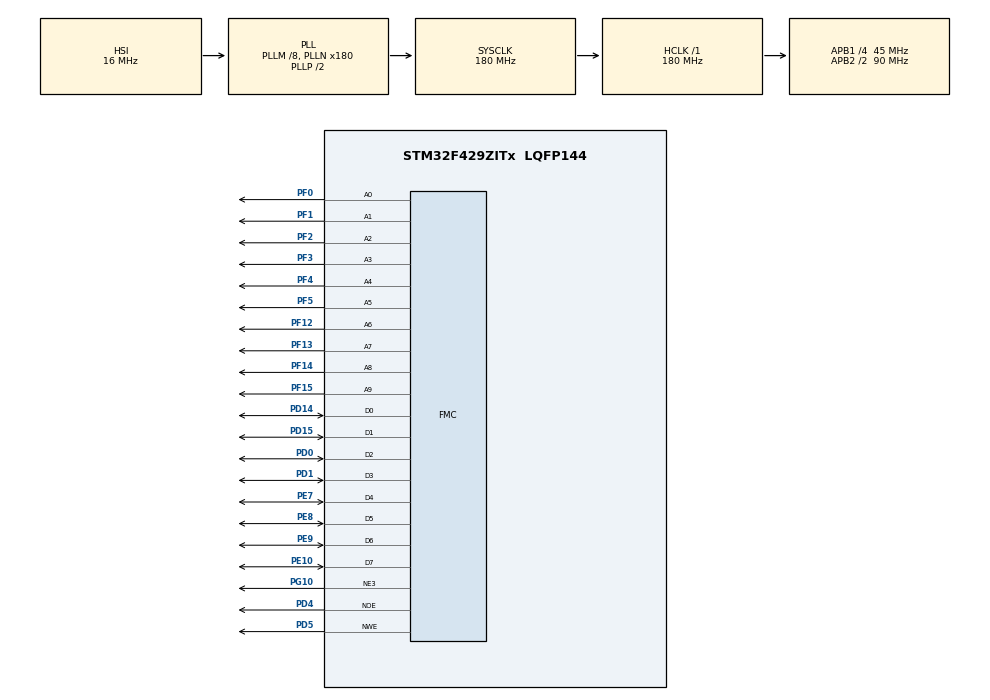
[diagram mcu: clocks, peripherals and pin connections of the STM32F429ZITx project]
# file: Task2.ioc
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FMC.ExtendedMode1=FMC_EXTENDED_MODE_ENABLE
FMC.WriteOperation1=FMC_WRITE_OPERATION_ENABLE
Mcu.Family=STM32F4
Mcu.Name=STM32F429ZITx
Mcu.Package=LQFP144
NVIC.PriorityGroup=NVIC_PRIORITYGROUP_4
PD0.Signal=FMC_D2_DA2
PD1.Signal=FMC_D3_DA3
PD14.Signal=FMC_D0_DA0
PD15.Signal=FMC_D1_DA1
PD4.Signal=FMC_NOE
PD5.Signal=FMC_NWE
PE10.Signal=FMC_D7_DA7
PE7.Signal=FMC_D4_DA4
PE8.Signal=FMC_D5_DA5
PE9.Signal=FMC_D6_DA6
PF0.Signal=FMC_A0
PF1.Signal=FMC_A1
PF12.Signal=FMC_A6
PF13.Signal=FMC_A7
PF14.Signal=FMC_A8
PF15.Signal=FMC_A9
PF2.Signal=FMC_A2
PF3.Signal=FMC_A3
PF4.Signal=FMC_A4
PF5.Signal=FMC_A5
PG10.Mode=NorPsramChipSelect3_1
PG10.Signal=FMC_NE3
PH0/OSC_IN.Mode=HSE-External-Oscillator
PH0/OSC_IN.Signal=RCC_OSC_IN
PH1/OSC_OUT.Mode=HSE-External-Oscillator
PH1/OSC_OUT.Signal=RCC_OSC_OUT
ProjectManager.HeapSize=0x200
ProjectManager.StackSize=0x400
ProjectManager.TargetToolchain=EWARM V8.32
RCC.48MHZClocksFreq_Value=90000000
RCC.AHBFreq_Value=180000000
RCC.APB1CLKDivider=RCC_HCLK_DIV4
RCC.APB1Freq_Value=45000000
RCC.APB1TimFreq_Value=90000000
RCC.APB2CLKDivider=RCC_HCLK_DIV2
RCC.APB2Freq_Value=90000000
RCC.APB2TimFreq_Value=180000000
RCC.CortexFreq_Value=180000000
RCC.HCLKFreq_Value=180000000
RCC.HSE_VALUE=8000000
RCC.HSI_VALUE=16000000
RCC.LSE_VALUE=32768
RCC.PLLM=8
RCC.PLLN=180
RCC.SYSCLKFreq_VALUE=180000000
RCC.SYSCLKSource=RCC_SYSCLKSOURCE_PLLCLK
RCC.VCOOutputFreq_Value=360000000
SH.FMC_A0.0=FMC_A0,10b-a1
SH.FMC_A1.0=FMC_A1,10b-a1
SH.FMC_A2.0=FMC_A2,10b-a1
SH.FMC_A3.0=FMC_A3,10b-a1
SH.FMC_A4.0=FMC_A4,10b-a1
SH.FMC_A5.0=FMC_A5,10b-a1
SH.FMC_A6.0=FMC_A6,10b-a1
SH.FMC_A7.0=FMC_A7,10b-a1
SH.FMC_A8.0=FMC_A8,10b-a1
SH.FMC_A9.0=FMC_A9,10b-a1
SH.FMC_D0_DA0.0=FMC_D0,8b-d1
SH.FMC_D1_DA1.0=FMC_D1,8b-d1
SH.FMC_D2_DA2.0=FMC_D2,8b-d1
SH.FMC_D3_DA3.0=FMC_D3,8b-d1
SH.FMC_D4_DA4.0=FMC_D4,8b-d1
SH.FMC_D5_DA5.0=FMC_D5,8b-d1
SH.FMC_D6_DA6.0=FMC_D6,8b-d1
SH.FMC_D7_DA7.0=FMC_D7,8b-d1
SH.FMC_NOE.0=FMC_NOE,Sram1
SH.FMC_NWE.0=FMC_NWE,Sram1
board=custom

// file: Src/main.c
/* USER CODE BEGIN Header */
/**
  ******************************************************************************
  * @file           : main.c
  * @brief          : Main program body
  ******************************************************************************
  * @attention
  *
  * <h2><center>&copy; Copyright (c) 2020 STMicroelectronics.
  * All rights reserved.</center></h2>
  *
  * This software component is licensed by ST under BSD 3-Clause license,
  * the "License"; You may not use this file except in compliance with the
  * License. You may obtain a copy of the License at:
  *                        opensource.org/licenses/BSD-3-Clause
  *
  ******************************************************************************
  */
/* USER CODE END Header */

#include "main.h"
#include "stdio.h"

SRAM_HandleTypeDef hsram1;

/* USER CODE BEGIN PV */
uint16_t addr = 0x0000;
uint8_t readData = 0x0000;
uint8_t buffer[15] = {0x0011,0x0022,0x0033,0x0044,0x0055,0x0066,0x0077,0x0088,0x0099,0x00aa,0x00bb,0x00cc,0x00dd,0x00ee,0x00ff};
/* USER CODE END PV */

void SystemClock_Config(void);
static void MX_GPIO_Init(void);
static void MX_FMC_Init(void);

int main(void)
{

  /* MCU Configuration--------------------------------------------------------*/

  /* Reset of all peripherals, Initializes the Flash interface and the Systick. */
  HAL_Init();

  /* Configure the system clock */
  SystemClock_Config();

  /* Initialize all configured peripherals */
  MX_GPIO_Init();
  MX_FMC_Init();
  /* Infinite loop */
  /* USER CODE BEGIN WHILE */
  while (1)
  {

    while (addr != 0x03FF){
      for (int i = 0; i < sizeof(buffer); i++){
          HAL_SRAM_Write_8b(&hsram1, (uint32_t*)addr, (uint8_t*)buffer[i], 0x00000008);
          addr++;
      }
    }
    addr =0x0000;
    while (addr != 0x03FF){
      for (int i = 0; i < sizeof(buffer); i++){
          HAL_SRAM_Read_8b(&hsram1, (uint32_t*)addr, (uint8_t*)readData, 0x0008);
          printf("%x", readData);
          addr++;
      }
    }
    /* USER CODE END WHILE */

}
}

void SystemClock_Config(void)
{
  RCC_OscInitTypeDef RCC_OscInitStruct = {0};
  RCC_ClkInitTypeDef RCC_ClkInitStruct = {0};

  /** Configure the main internal regulator output voltage
  */
  __HAL_RCC_PWR_CLK_ENABLE();
  __HAL_PWR_VOLTAGESCALING_CONFIG(PWR_REGULATOR_VOLTAGE_SCALE1);
  /** Initializes the CPU, AHB and APB busses clocks
  */
  RCC_OscInitStruct.OscillatorType = RCC_OSCILLATORTYPE_HSI;
  RCC_OscInitStruct.HSIState = RCC_HSI_ON;
  RCC_OscInitStruct.HSICalibrationValue = RCC_HSICALIBRATION_DEFAULT;
  RCC_OscInitStruct.PLL.PLLState = RCC_PLL_ON;
  RCC_OscInitStruct.PLL.PLLSource = RCC_PLLSOURCE_HSI;
  RCC_OscInitStruct.PLL.PLLM = 8;
  RCC_OscInitStruct.PLL.PLLN = 180;
  RCC_OscInitStruct.PLL.PLLP = RCC_PLLP_DIV2;
  RCC_OscInitStruct.PLL.PLLQ = 4;
  if (HAL_RCC_OscConfig(&RCC_OscInitStruct) != HAL_OK)
  {
    Error_Handler();
  }
  /** Activate the Over-Drive mode
  */
  if (HAL_PWREx_EnableOverDrive() != HAL_OK)
  {
    Error_Handler();
  }
  /** Initializes the CPU, AHB and APB busses clocks
  */
  RCC_ClkInitStruct.ClockType = RCC_CLOCKTYPE_HCLK|RCC_CLOCKTYPE_SYSCLK
                              |RCC_CLOCKTYPE_PCLK1|RCC_CLOCKTYPE_PCLK2;
  RCC_ClkInitStruct.SYSCLKSource = RCC_SYSCLKSOURCE_PLLCLK;
  RCC_ClkInitStruct.AHBCLKDivider = RCC_SYSCLK_DIV1;
  RCC_ClkInitStruct.APB1CLKDivider = RCC_HCLK_DIV4;
  RCC_ClkInitStruct.APB2CLKDivider = RCC_HCLK_DIV2;

  if (HAL_RCC_ClockConfig(&RCC_ClkInitStruct, FLASH_LATENCY_5) != HAL_OK)
  {
    Error_Handler();
  }
}

/* FMC initialization function */
static void MX_FMC_Init(void)
{

  FMC_NORSRAM_TimingTypeDef Timing = {0};
  FMC_NORSRAM_TimingTypeDef ExtTiming = {0};

  /** Perform the SRAM1 memory initialization sequence
  */
  hsram1.Instance = FMC_NORSRAM_DEVICE;
  hsram1.Extended = FMC_NORSRAM_EXTENDED_DEVICE;
  /* hsram1.Init */
  hsram1.Init.NSBank = FMC_NORSRAM_BANK3;
  hsram1.Init.DataAddressMux = FMC_DATA_ADDRESS_MUX_DISABLE;
  hsram1.Init.MemoryType = FMC_MEMORY_TYPE_SRAM;
  hsram1.Init.MemoryDataWidth = FMC_NORSRAM_MEM_BUS_WIDTH_8;
  hsram1.Init.BurstAccessMode = FMC_BURST_ACCESS_MODE_DISABLE;
  hsram1.Init.WaitSignalPolarity = FMC_WAIT_SIGNAL_POLARITY_LOW;
  hsram1.Init.WrapMode = FMC_WRAP_MODE_DISABLE;
  hsram1.Init.WaitSignalActive = FMC_WAIT_TIMING_BEFORE_WS;
  hsram1.Init.WriteOperation = FMC_WRITE_OPERATION_ENABLE;
  hsram1.Init.WaitSignal = FMC_WAIT_SIGNAL_DISABLE;
  hsram1.Init.ExtendedMode = FMC_EXTENDED_MODE_ENABLE;
  hsram1.Init.AsynchronousWait = FMC_ASYNCHRONOUS_WAIT_DISABLE;
  hsram1.Init.WriteBurst = FMC_WRITE_BURST_DISABLE;
  hsram1.Init.ContinuousClock = FMC_CONTINUOUS_CLOCK_SYNC_ONLY;
  hsram1.Init.PageSize = FMC_PAGE_SIZE_NONE;
  /* Timing */
  Timing.AddressSetupTime = 15;
  Timing.AddressHoldTime = 15;
  Timing.DataSetupTime = 255;
  Timing.BusTurnAroundDuration = 15;
  Timing.CLKDivision = 16;
  Timing.DataLatency = 17;
  Timing.AccessMode = FMC_ACCESS_MODE_A;
  /* ExtTiming */
  ExtTiming.AddressSetupTime = 15;
  ExtTiming.AddressHoldTime = 15;
  ExtTiming.DataSetupTime = 255;
  ExtTiming.BusTurnAroundDuration = 15;
  ExtTiming.CLKDivision = 16;
  ExtTiming.DataLatency = 17;
  ExtTiming.AccessMode = FMC_ACCESS_MODE_A;

  if (HAL_SRAM_Init(&hsram1, &Timing, &ExtTiming) != HAL_OK)
  {
    Error_Handler( );
  }

}

static void MX_GPIO_Init(void)
{

  /* GPIO Ports Clock Enable */
  __HAL_RCC_GPIOF_CLK_ENABLE();
  __HAL_RCC_GPIOH_CLK_ENABLE();
  __HAL_RCC_GPIOE_CLK_ENABLE();
  __HAL_RCC_GPIOD_CLK_ENABLE();
  __HAL_RCC_GPIOG_CLK_ENABLE();

}

void Error_Handler(void)
{
}

/************************ (C) COPYRIGHT STMicroelectronics *****END OF FILE****/
